VERSION "HIPBNYYYYYYYYYYYYYYYYYYYYYYYYYYYYYYYYYYYYY/4/%%%/4/'%**4YYY///"

NS_ :

BS_:

BU_: Pegasus Marvel Laptop Stark Xavier stark Gtake

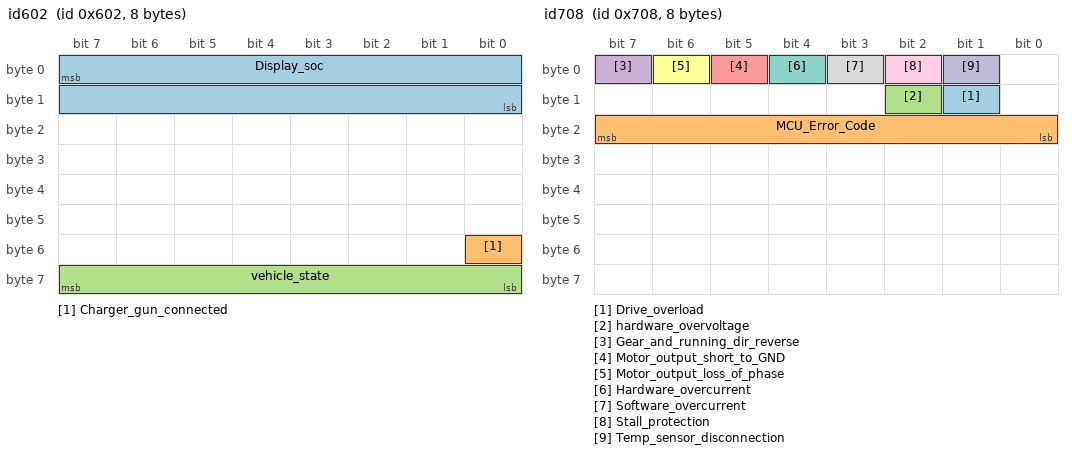
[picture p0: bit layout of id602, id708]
BO_ 1538 id602: 8 Stark
 SG_ Display_soc : 7|16@0+ (0.1,0) [0|0] "%" Vector__XXX
 SG_ Charger_gun_connected : 48|1@1+ (1,0) [0|2] "" Vector__XXX
 SG_ vehicle_state : 63|8@0+ (1,0) [0|10] "" Vector__XXX

BO_ 1539 id603: 8 Stark
 SG_ Odometer : 23|32@0+ (0.01,0) [0|429496729.5] "Km" Vector__XXX

BO_ 1542 id606: 8 Stark
 SG_ Aux_battery_voltage : 15|16@0+ (0.01,0) [0|655.35] "V" Vector__XXX

BO_ 1800 id708: 8 Gtake
 SG_ Drive_overload : 9|1@1+ (1,0) [0|1] "" Vector__XXX
 SG_ MCU_Error_Code : 16|8@1+ (1,0) [0|255] "" Vector__XXX
 SG_ hardware_overvoltage : 10|1@1+ (1,0) [0|1] "" Vector__XXX
 SG_ Gear_and_running_dir_reverse : 7|1@1+ (1,0) [0|1] "" Vector__XXX
 SG_ Motor_output_short_to_GND : 5|1@1+ (1,0) [0|1] "" Vector__XXX
 SG_ Motor_output_loss_of_phase : 6|1@1+ (1,0) [0|1] "" Vector__XXX
 SG_ Hardware_overcurrent : 4|1@1+ (1,0) [0|1] "" Vector__XXX
 SG_ Software_overcurrent : 3|1@1+ (1,0) [0|1] "" Vector__XXX
 SG_ Stall_protection : 2|1@1+ (1,0) [0|1] "" Vector__XXX
 SG_ Temp_sensor_disconnection : 1|1@1+ (1,0) [0|1] "" Vector__XXX

BO_ 1828 id724: 8 Gtake
 SG_ Motor_Torque_Estimated : 0|16@1- (0.1,0) [-3276.8|3276.7] "Nm" Vector__XXX

BO_ 1815 id717: 8 Gtake
 SG_ Operating_frequency : 0|16@1- (1,0) [-32768|32767] "Hz" Vector__XXX

BO_ 1814 id716: 8 Gtake
 SG_ VRMS : 40|8@1+ (1,0) [0|255] "V rms" Vector__XXX
 SG_ ARMS : 48|16@1+ (1,0) [0|65535] "A rms" Vector__XXX

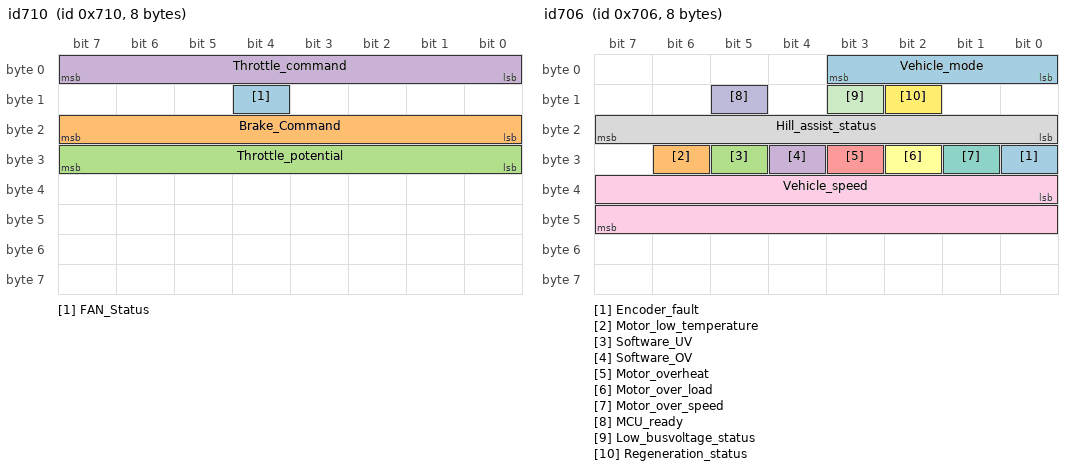
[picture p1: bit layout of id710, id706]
BO_ 1808 id710: 8 Gtake
 SG_ FAN_Status : 12|1@1+ (1,0) [0|1] "" Vector__XXX
 SG_ Brake_Command : 16|8@1+ (1,0) [0|1] "" Vector__XXX
 SG_ Throttle_potential : 24|8@1+ (0.1,0) [0|25.5] "V" Vector__XXX
 SG_ Throttle_command : 0|8@1+ (1,0) [0|255] "%" Vector__XXX

BO_ 1813 id715: 8 Gtake
 SG_ Capacitor_Voltage : 32|8@1+ (1,0) [0|255] "V" Vector__XXX
 SG_ RPM : 48|16@1+ (1,0) [0|65535] "RPM" Vector__XXX

BO_ 1798 id706: 8 Gtake
 SG_ Encoder_fault : 24|1@1+ (1,0) [0|1] "" Vector__XXX
 SG_ Motor_low_temperature : 30|1@1+ (1,0) [0|1] "" Vector__XXX
 SG_ Software_UV : 29|1@1+ (1,0) [0|1] "" Vector__XXX
 SG_ Software_OV : 28|1@1+ (1,0) [0|1] "" Vector__XXX
 SG_ Motor_overheat : 27|1@1+ (1,0) [0|1] "" Vector__XXX
 SG_ Motor_over_load : 26|1@1+ (1,0) [0|1] "" Vector__XXX
 SG_ Motor_over_speed : 25|1@1+ (1,0) [0|0] "" Vector__XXX
 SG_ Hill_assist_status : 16|8@1+ (1,0) [0|255] "" Vector__XXX
 SG_ Vehicle_speed : 32|16@1- (0.1,0) [-3276.8|3276.7] "Kmph" Vector__XXX
 SG_ MCU_ready : 13|1@1+ (1,0) [0|1] "" Vector__XXX
 SG_ Low_busvoltage_status : 11|1@1+ (1,0) [0|0] "" Vector__XXX
 SG_ Regeneration_status : 10|1@1+ (1,0) [0|1] "" Vector__XXX
 SG_ Vehicle_mode : 0|4@1+ (1,0) [0|15] "" Vector__XXX

BO_ 1797 id705: 8 Gtake
 SG_ MCU_Temperature : 8|8@1+ (1,-50) [-50|205] "" Vector__XXX
 SG_ Motor_Temperature : 0|8@1+ (1,-50) [-50|205] "" Vector__XXX

BO_ 1025 id401: 8 Xavier
 SG_ Display_Speed : 0|8@1+ (1,0) [0|255] "Kmph" Vector__XXX

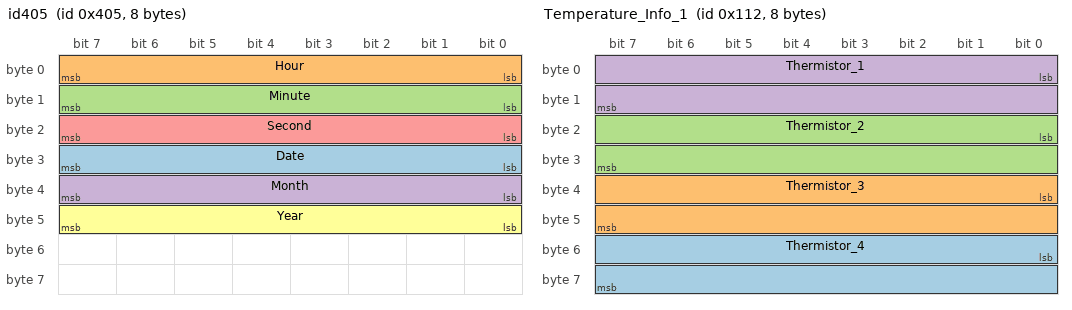
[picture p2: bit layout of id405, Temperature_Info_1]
BO_ 1029 id405: 8 Xavier
 SG_ Date : 24|8@1+ (1,0) [0|0] "" Vector__XXX
 SG_ Hour : 0|8@1+ (1,0) [0|0] "" Vector__XXX
 SG_ Minute : 8|8@1+ (1,0) [0|0] "" Vector__XXX
 SG_ Month : 32|8@1+ (1,0) [0|0] "" Vector__XXX
 SG_ Second : 16|8@1+ (1,0) [0|0] "" Vector__XXX
 SG_ Year : 40|8@1+ (1,0) [0|0] "" Vector__XXX

BO_ 285 Balancing_Bit_Mask: 3 Vector__XXX
 SG_ Balancing_Mask_Indication : 0|24@1+ (1,0) [0|16777215] "" Vector__XXX

BO_ 284 Battery_Capacity_Info: 8 Vector__XXX
 SG_ Pack_Capacity : 16|16@1+ (0.1,0) [0|6553.5] "Ah" Vector__XXX

BO_ 290 Temperature_Info_2: 4 Vector__XXX
 SG_ Available_Discharge_Energy : 16|16@1+ (1,0) [0|65535] "Wh" Vector__XXX
 SG_ Thermistor_5 : 0|16@1+ (0.1,0) [-128|127] "degC" Vector__XXX

BO_ 274 Temperature_Info_1: 8 Vector__XXX
 SG_ Thermistor_4 : 48|16@1+ (0.1,0) [-128|127] "degC" Vector__XXX
 SG_ Thermistor_3 : 32|16@1+ (0.1,0) [-128|127] "degC" Vector__XXX
 SG_ Thermistor_2 : 16|16@1+ (0.1,0) [-128|127] "degC" Vector__XXX
 SG_ Thermistor_1 : 0|16@1+ (0.1,0) [-128|127] "degC" Vector__XXX

BO_ 280 Cell_Voltage_Info_6: 4 Vector__XXX
 SG_ Cell_Voltage_20 : 16|16@1+ (0.1,0) [0|6553.5] "mV" Vector__XXX
 SG_ Cell_Voltage_19 : 0|16@1+ (0.1,0) [0|6553.5] "mV" Vector__XXX

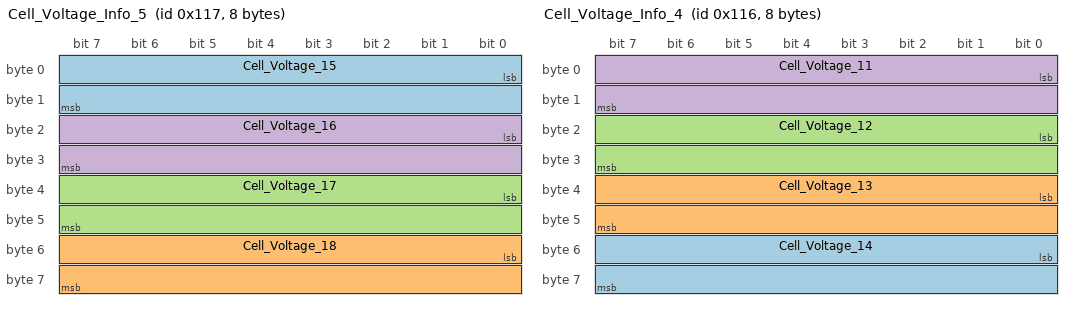
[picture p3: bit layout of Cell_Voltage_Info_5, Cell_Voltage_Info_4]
BO_ 279 Cell_Voltage_Info_5: 8 Vector__XXX
 SG_ Cell_Voltage_15 : 0|16@1+ (0.1,0) [0|6553.5] "mV" Vector__XXX
 SG_ Cell_Voltage_18 : 48|16@1+ (0.1,0) [0|6553.5] "mV" Vector__XXX
 SG_ Cell_Voltage_17 : 32|16@1+ (0.1,0) [0|6553.5] "mV" Vector__XXX
 SG_ Cell_Voltage_16 : 16|16@1+ (0.1,0) [0|6553.5] "mV" Vector__XXX

BO_ 278 Cell_Voltage_Info_4: 8 Vector__XXX
 SG_ Cell_Voltage_14 : 48|16@1+ (0.1,0) [0|6553.5] "mV" Vector__XXX
 SG_ Cell_Voltage_13 : 32|16@1+ (0.1,0) [0|6553.5] "mV" Vector__XXX
 SG_ Cell_Voltage_12 : 16|16@1+ (0.1,0) [0|6553.5] "mV" Vector__XXX
 SG_ Cell_Voltage_11 : 0|16@1+ (0.1,0) [0|6553.5] "mV" Vector__XXX

BO_ 277 Cell_Voltage_Info_3: 4 Vector__XXX
 SG_ Cell_Voltage_9 : 0|16@1+ (0.1,0) [0|6553.5] "mV" Vector__XXX
 SG_ Cell_Voltage_10 : 16|16@1+ (0.1,0) [0|6553.5] "mV" Vector__XXX

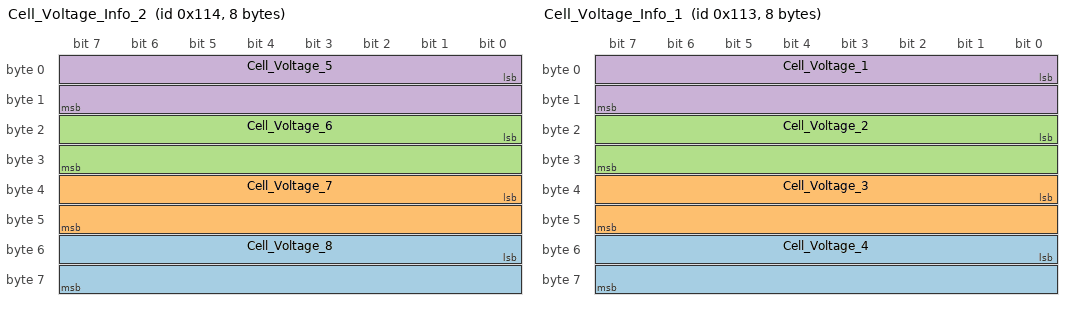
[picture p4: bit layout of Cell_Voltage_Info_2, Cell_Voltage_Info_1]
BO_ 276 Cell_Voltage_Info_2: 8 Vector__XXX
 SG_ Cell_Voltage_8 : 48|16@1+ (0.1,0) [0|6553.5] "mV" Vector__XXX
 SG_ Cell_Voltage_7 : 32|16@1+ (0.1,0) [0|6553.5] "mV" Vector__XXX
 SG_ Cell_Voltage_6 : 16|16@1+ (0.1,0) [0|6553.5] "mV" Vector__XXX
 SG_ Cell_Voltage_5 : 0|16@1+ (0.1,0) [0|6553.5] "mV" Vector__XXX

BO_ 275 Cell_Voltage_Info_1: 8 Vector__XXX
 SG_ Cell_Voltage_4 : 48|16@1+ (0.1,0) [0|6553.5] "mV" Vector__XXX
 SG_ Cell_Voltage_3 : 32|16@1+ (0.1,0) [0|6553.5] "mV" Vector__XXX
 SG_ Cell_Voltage_2 : 16|16@1+ (0.1,0) [0|6553.5] "mV" Vector__XXX
 SG_ Cell_Voltage_1 : 0|16@1+ (0.1,0) [0|6553.5] "mV" Vector__XXX

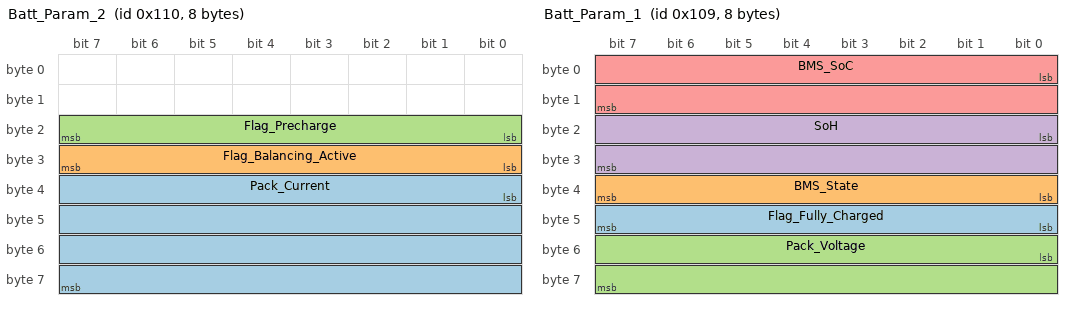
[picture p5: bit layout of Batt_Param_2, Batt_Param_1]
BO_ 272 Batt_Param_2: 8 Vector__XXX
 SG_ Pack_Current : 32|32@1- (1e-005,0) [-21474.8|21474.8] "A" Vector__XXX
 SG_ Flag_Balancing_Active : 24|8@1+ (1,0) [0|1] "" Vector__XXX
 SG_ Flag_Precharge : 16|8@1+ (1,0) [0|1] "" Vector__XXX

BO_ 265 Batt_Param_1: 8 Vector__XXX
 SG_ Flag_Fully_Charged : 40|8@1+ (1,0) [0|0] "" Vector__XXX
 SG_ BMS_State : 32|8@1+ (1,0) [0|0] "" Vector__XXX
 SG_ Pack_Voltage : 48|16@1+ (0.1,0) [0|6553.5] "V" Vector__XXX
 SG_ SoH : 16|16@1+ (0.01,0) [0|655.35] "%" Vector__XXX
 SG_ BMS_SoC : 0|16@1+ (0.01,0) [0|655.35] "%" Vector__XXX

BO_ 611 ERR_OpenConnection: 1 Vector__XXX
 SG_ OpenConnection : 0|8@1+ (1,0) [0|1] "" Vector__XXX

BO_ 606 ERR_ShortCircuit: 1 Vector__XXX
 SG_ SCD_Flag : 0|8@1+ (1,0) [0|1] "" Vector__XXX

BO_ 605 ERR_Overload: 1 Vector__XXX
 SG_ Overload : 0|8@1+ (1,0) [0|1] "" Vector__XXX

BO_ 604 ERR_OverTemperature: 1 Vector__XXX
 SG_ BATT_OVERTEMP : 0|8@1+ (1,0) [0|1] "" Vector__XXX

BO_ 603 ERR_UnderVoltage: 1 Vector__XXX
 SG_ UV_ERROR_BATT : 0|8@1+ (1,0) [0|1] "" Vector__XXX

BO_ 602 ERR_OverVoltage: 1 Vector__XXX
 SG_ OV_ERROR_BATT : 0|8@1+ (1,0) [0|1] "" Vector__XXX

BA_DEF_ SG_  "SigType" ENUM  "Default","Range","RangeSigned","ASCII","Discrete","Control","ReferencePGN","DTC","StringDelimiter","StringLength","StringLengthControl","MessageCounter","MessageChecksum";
BA_DEF_ SG_  "GenSigSendType" ENUM  "Cyclic","OnWrite","OnWriteWithRepetition","OnChange","OnChangeWithRepetition","IfActive","IfActiveWithRepetition","NoSigSendType";
BA_DEF_ SG_  "GenSigStartValue" INT 0 2147483647;
BA_DEF_ BO_  "GenMsgSendType" ENUM  "cyclic","NotUsed","IfActive","NotUsed","NotUsed","NotUsed","NotUsed","NotUsed","noMsgSendType";
BA_DEF_  "DBName" STRING ;
BA_DEF_ BO_  "VFrameFormat" ENUM  "StandardCAN","ExtendedCAN","reserved","J1939PG";
BA_DEF_ SG_  "SigType" ENUM  "Default","Range","RangeSigned","ASCII","Discrete","Control","ReferencePGN","DTC","StringDelimiter","StringLength","StringLengthControl","MessageCounter","MessageChecksum";
BA_DEF_ SG_  "GenSigSendType" ENUM  "Cyclic","OnWrite","OnWriteWithRepetition","OnChange","OnChangeWithRepetition","IfActive","IfActiveWithRepetition","NoSigSendType";
BA_DEF_ SG_  "GenSigStartValue" INT 0 2147483647;
BA_DEF_ BO_  "GenMsgSendType" ENUM  "cyclic","NotUsed","IfActive","NotUsed","NotUsed","NotUsed","NotUsed","NotUsed","noMsgSendType";
BA_DEF_  "DBName" STRING ;
BA_DEF_ BO_  "VFrameFormat" ENUM  "StandardCAN","ExtendedCAN","reserved","J1939PG";
BA_DEF_DEF_  "SigType" "Default";
BA_DEF_DEF_  "GenSigSendType" "Cyclic";
BA_DEF_DEF_  "GenSigStartValue" 0;
BA_DEF_DEF_  "GenMsgSendType" "cyclic";
BA_DEF_DEF_  "DBName" "";
BA_DEF_DEF_  "VFrameFormat" "StandardCAN";
BA_DEF_DEF_  "SigType" "Default";
BA_DEF_DEF_  "GenSigSendType" "Cyclic";
BA_DEF_DEF_  "GenSigStartValue" 0;
BA_DEF_DEF_  "GenMsgSendType" "cyclic";
BA_DEF_DEF_  "DBName" "";
BA_DEF_DEF_  "VFrameFormat" "StandardCAN";
BA_ "GenSigStartValue" SG_ 1797 MCU_Temperature 50;
BA_ "GenSigStartValue" SG_ 1797 Motor_Temperature 50;
BA_ "DBName" "D03CAN";
BA_ "DBName" "D03CAN";
VAL_ 1538 Charger_gun_connected 0 "0" 1 "1" ;
VAL_ 1538 vehicle_state 0 "0" 1 "1" 2 "2" 3 "3" ;
VAL_ 1800 Drive_overload 1 "1" 0 "0" ;
VAL_ 1800 hardware_overvoltage 0 "0" 1 "1" ;
VAL_ 1800 Gear_and_running_dir_reverse 1 "1" 0 "0" ;
VAL_ 1800 Motor_output_short_to_GND 1 "1" 0 "0" ;
VAL_ 1800 Motor_output_loss_of_phase 1 "1" 0 "0" ;
VAL_ 1800 Hardware_overcurrent 1 "1" 0 "0" ;
VAL_ 1800 Software_overcurrent 1 "1" 0 "0" ;
VAL_ 1800 Stall_protection 1 "1" 0 "0" ;
VAL_ 1800 Temp_sensor_disconnection 1 "1" 0 "0" ;
VAL_ 1808 FAN_Status 0 "0" 1 "1" ;
VAL_ 1808 Brake_Command 1 "1" 0 "0" ;
VAL_ 1798 Encoder_fault 1 "1" 0 "0" ;
VAL_ 1798 Motor_low_temperature 1 "1" 0 "0" ;
VAL_ 1798 Software_UV 1 "1" 0 "0" ;
VAL_ 1798 Software_OV 1 "1" 0 "0" ;
VAL_ 1798 Motor_overheat 1 "1" 0 "0" ;
VAL_ 1798 Motor_over_load 1 "1" 0 "0" ;
VAL_ 1798 Motor_over_speed 1 "1" 0 "0" ;
VAL_ 1798 MCU_ready 1 "1" 0 "0" ;
VAL_ 1798 Low_busvoltage_status 1 "1" 0 "0" ;
VAL_ 1798 Regeneration_status 1 "1" 0 "0" ;
VAL_ 1798 Vehicle_mode 8 "Thunder" 4 "Reverse" 2 "Eco" 1 "Neutral" ;
